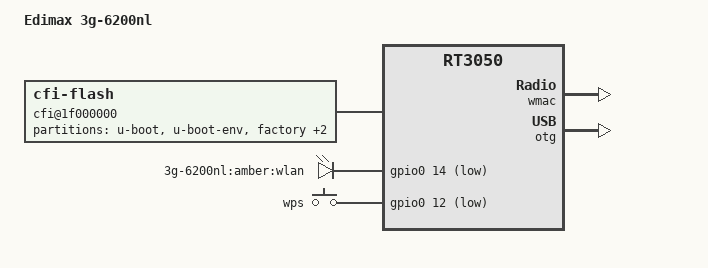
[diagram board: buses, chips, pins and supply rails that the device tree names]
/dts-v1/;

#include "rt3050.dtsi"

/ {
	compatible = "3G-6200NL", "ralink,rt3050-soc";
	model = "Edimax 3g-6200nl";

	cfi@1f000000 {
		compatible = "cfi-flash";
		reg = <0x1f000000 0x800000>;
		bank-width = <2>;
		device-width = <2>;
		#address-cells = <1>;
		#size-cells = <1>;

		partition@0 {
			label = "u-boot";
			reg = <0x0 0x30000>;
			read-only;
		};

		partition@30000 {
			label = "u-boot-env";
			reg = <0x30000 0x10000>;
			read-only;
		};

		factory: partition@40000 {
			label = "factory";
			reg = <0x40000 0x10000>;
			read-only;
		};

		partition@3e0000 {
			label = "cimage";
			reg = <0x3e0000 0x20000>;
			read-only;
		};

		partition@50000 {
			label = "firmware";
			reg = <0x50000 0x390000>;
		};
	};

	gpio-leds {
		compatible = "gpio-leds";

		wlan {
			label = "3g-6200nl:amber:wlan";
			gpios = <&gpio0 14 1>;
		};
	};

	gpio-keys-polled {
		compatible = "gpio-keys-polled";
		#address-cells = <1>;
		#size-cells = <0>;
		poll-interval = <20>;

		wps {
			label = "wps";
			gpios = <&gpio0 12 1>;
			linux,code = <0x211>;
		};
	};
};

&pinctrl {
	state_default: pinctrl0 {
		gpio {
			ralink,group = "spi", "i2c", "jtag", "rgmii", "mdio", "uartf";
			ralink,function = "gpio";
		};
	};
};

&ethernet {
	mtd-mac-address = <&factory 0x4>;
};

&esw {
	mediatek,portmap = <0x2f>;
};

&wmac {
	ralink,mtd-eeprom = <&factory 0>;
};

&otg {
	status = "okay";
};
